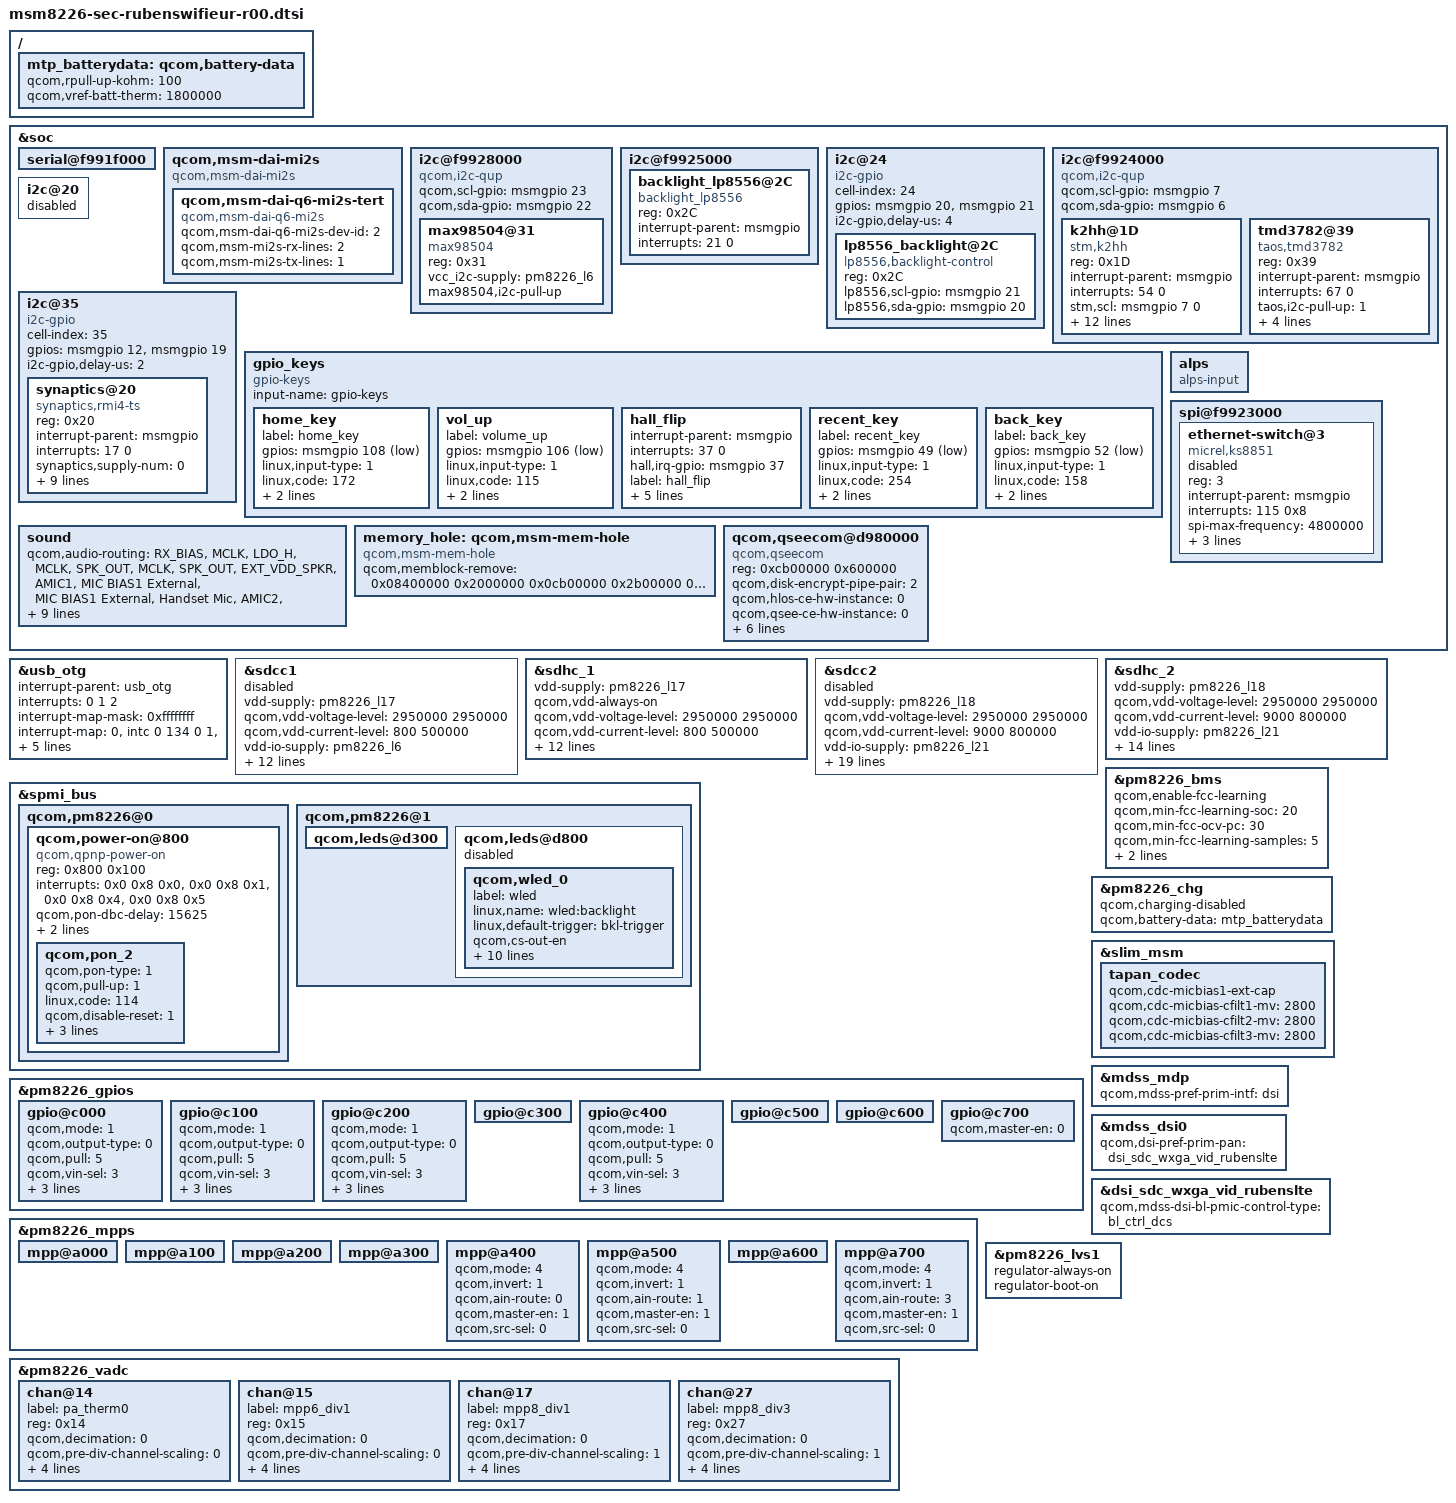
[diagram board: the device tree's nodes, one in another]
/* Copyright (c) 2013, The Linux Foundation. All rights reserved.
 *
 * This program is free software; you can redistribute it and/or modify
 * it under the terms of the GNU General Public License version 2 and
 * only version 2 as published by the Free Software Foundation.
 *
 * This program is distributed in the hope that it will be useful,
 * but WITHOUT ANY WARRANTY; without even the implied warranty of
 * MERCHANTABILITY or FITNESS FOR A PARTICULAR PURPOSE.  See the
 * GNU General Public License for more details.
 */

/include/ "msm8226-camera-sensor-mtp-rubenswifi_eur-r00.dtsi"
/include/ "dsi_panel_sdc_wxga_video_rubenslte.dtsi"
/include/ "msm8226-sec-rubenswifieur-battery-data.dtsi"

&soc {
	serial@f991f000 {
		status = "ok";
	};
/*# CONFIG_SND_SOC_MAX98504*/
		qcom,msm-dai-mi2s {
			compatible = "qcom,msm-dai-mi2s";
			qcom,msm-dai-q6-mi2s-tert {
			compatible = "qcom,msm-dai-q6-mi2s";
			qcom,msm-dai-q6-mi2s-dev-id = <2>;
			qcom,msm-mi2s-rx-lines = <2>;
			qcom,msm-mi2s-tx-lines = <1>;
		};
	};
	
    	i2c@f9928000 {	 /*BLSP-1 QUP-6*/
		compatible = "qcom,i2c-qup";
		qcom,scl-gpio = <&msmgpio 23 0>;
		qcom,sda-gpio = <&msmgpio 22 0>;
		max98504@31 {
			compatible = "max98504";
			reg = <0x31>;
			vcc_i2c-supply = <&pm8226_l6>;
			max98504,i2c-pull-up;
		};
	};// CONFIG_SND_SOC_MAX98504
	
	 /*
	i2c@f9925000 {
		sec-nfc@27 {
			compatible = "sec-nfc";
			reg = <0x27>;
			interrupt-parent = <&msmgpio>;
			interrupts = <21 0>;
			vdd_nfc-supply = <&pm8226_l6>;
			sec-nfc,en-gpio = <&msmgpio 36 0x1>;
			sec-nfc,wake-gpio = <&msmgpio 20 0x00>;
		};
	};*/

	i2c@f9925000 { /* BLSP1 QUP2 */
/*	i2c@75 {
		cell-index = <75>;
		compatible = "i2c-gpio";
		gpios = <&msmgpio 20 0
			&msmgpio 21 0>;};*/

	backlight_lp8556@2C {
			compatible = "backlight_lp8556";
			reg = <0x2C>;
			interrupt-parent = <&msmgpio>;
			interrupts = <21 0>;
		};
	};

	i2c@24 {
                cell-index = <24>;
                compatible = "i2c-gpio";
                gpios = <&msmgpio 20 0 /* sda */
                                &msmgpio 21 0 /* scl */
                >;

                i2c-gpio,delay-us = <4>;

                lp8556_backlight@2C {
                                compatible = "lp8556,backlight-control";
                                reg = <0x2C>;
                                lp8556,scl-gpio = <&msmgpio 21 0x00>;
                                lp8556,sda-gpio = <&msmgpio 20 0x00>;
                };
        };

	i2c@f9924000 { /* BLSP1 QUP2 */
		compatible = "qcom,i2c-qup";
		qcom,scl-gpio = <&msmgpio 7 0>;
		qcom,sda-gpio = <&msmgpio 6 0>;
		k2hh@1D {
			compatible = "stm,k2hh";
			reg = <0x1D>;
			interrupt-parent = <&msmgpio>;
			interrupts = <54 0>;
			stm,scl = <&msmgpio 7 0>;
			stm,sda = <&msmgpio 6 0>;
			stm,irq_gpio = <&msmgpio 54 0x00>;
			stm,reg_vdd = "8226_l19";
			stm,reg_vio = "8226_lvs1";
			stm,axis_map_x = <1>;
			stm,axis_map_y = <0>;
			stm,axis_map_z = <2>;
			stm,negate_x = <0>;
			stm,negate_y = <1>;
			stm,negate_z = <1>;
			stm,poll_interval = <100>;
			stm,min_interval = <2>;
		};

		tmd3782@39 {
			compatible = "taos,tmd3782";
			reg = <0x39>;
			interrupt-parent = <&msmgpio>;
			interrupts = <67 0>;
			taos,i2c-pull-up = <1>;
			taos,reg_vdd = "8226_l19";
			taos,reg_vio = "8226_l6";
			taos,reg_ldo = "8226_l15";
			taos,irq_gpio = <&msmgpio 67 0x1>;
			status = "okay";
		};
	};

	i2c@20 {
		status="disabled";
	};

	i2c@35{
		cell-index = <35>;
		compatible = "i2c-gpio";
		gpios = <&msmgpio 12 0 /* sda */
				 &msmgpio 19 0 /* scl */
				>;
		i2c-gpio,delay-us = <2>;
                synaptics@20 {
                        compatible = "synaptics,rmi4-ts";
                        reg = <0x20>;
                        interrupt-parent = <&msmgpio>;
                        interrupts = <17 0>;
                        synaptics,supply-num = <0>;                     /* the number of regulators */
                        synaptics,external_ldo = <&msmgpio 31 0x01>; /*Touch En 1 gpio*/
                        synaptics,external_ldo2 = <&msmgpio 114 0x01>; /* Touch En2 gpio */
                        synaptics,irq-gpio = <&msmgpio 17 0x00>;
                        synaptics,reset-gpio = <&msmgpio 34 0x00>;
                        synaptics,i2c-pull-up = <1>;
                        synaptics,tsp-project = "RUBENS";
                        synaptics,tsp-coords = <1599 2559>;
                        synaptics,tsp-extra_config = <0 0 0 1>;
                        synaptics,id-gpio = <&msmgpio 55 0x01>;
                        /* <"pwrctrl", "N", "N", "irq no pull up, workaround"> */
                        /* Set regulators' voltage below. Search with "8941_l22", "8941_l10" */
                };

	};
	gpio_keys {
		compatible = "gpio-keys";
		input-name = "gpio-keys";

		home_key {
			label = "home_key";
			gpios = <&msmgpio 108 0x1>;
			linux,input-type = <1>;
			linux,code = <172>;
			gpio-key,wakeup;
			debounce-interval = <15>;
		};


		vol_up {
			label = "volume_up";
			gpios = <&msmgpio 106 0x1>;
			linux,input-type = <1>;
			linux,code = <115>;
			gpio-key,wakeup;
			debounce-interval = <15>;
		};

		hall_flip {
			interrupt-parent = <&msmgpio>;
			interrupts = <37 0>;
			hall,irq-gpio = <&msmgpio 37 0x00>;

			label = "hall_flip";
			gpios = <&msmgpio 37 0>;
			linux,input-type = <1>;
			linux,code = <0x15>;
			gpio-key,wakeup;
			debounce-interval = <15>;
		};
		recent_key {
			label = "recent_key";
			gpios = <&msmgpio 49 0x1>;
			linux,input-type = <1>;
			linux,code = <254>;
			gpio-key,wakeup;
			debounce-interval = <15>;
		};
		back_key {
			label = "back_key";
			gpios = <&msmgpio 52 0x1>;
			linux,input-type = <1>;
			linux,code = <158>;
			gpio-key,wakeup;
			debounce-interval = <15>;
		};
	};
	alps {
			compatible = "alps-input";
	};

	spi@f9923000 {
		ethernet-switch@3 {
			compatible = "micrel,ks8851";
			reg = <3>;
			interrupt-parent = <&msmgpio>;
			interrupts = <115 0x8>;
			spi-max-frequency = <4800000>;
			rst-gpio = <&msmgpio 114 0>;
			vdd-io-supply = <&pm8226_lvs1>;
			vdd-phy-supply = <&pm8226_lvs1>;
			status = "disable";
		};
	};

	sound {
		qcom,audio-routing =
			"RX_BIAS", "MCLK",
			"LDO_H", "MCLK",
			"SPK_OUT", "MCLK",
			"SPK_OUT", "EXT_VDD_SPKR",
			"AMIC1", "MIC BIAS1 External",
			"MIC BIAS1 External", "Handset Mic",
			"AMIC2", "MIC BIAS2 External",
			"MIC BIAS2 External", "Headset Mic",
			"AMIC3", "MIC BIAS3 External",
			"MIC BIAS3 External", "Sub Mic",
			"AMIC4", "MIC BIAS2 External",
			"MIC BIAS2 External", "ANCRight Headset Mic",
			"AMIC5", "MIC BIAS2 External",
			"MIC BIAS2 External", "ANCLeft Headset Mic";

		qcom,cdc-mclk-gpios = <&pm8226_gpios 1 0>;
		/*qcom,cdc-vdd-spkr-gpios = <&pm8226_gpios 2 0>;*/
		vdd-earjack-supply = <&pm8226_l19>;
	};

	memory_hole: qcom,msm-mem-hole {
		     compatible = "qcom,msm-mem-hole";
		     qcom,memblock-remove = <0x08400000 0x2000000
					     0x0cb00000 0x2b00000 /* Increase TZ apps region to 6MB (SR #0133393) + 1MB reserved for TIMA logging at 0xd100000 */
					     0x0fa00000 0x500000>; /* Address and Size of Hole */
	};

	qcom,qseecom@d980000 {
		compatible = "qcom,qseecom";
		reg = <0xcb00000 0x600000>;
		reg-names = "secapp-region";
		qcom,disk-encrypt-pipe-pair = <2>;
		qcom,hlos-ce-hw-instance = <0>;
		qcom,qsee-ce-hw-instance = <0>;
		qcom,msm-bus,name = "qseecom-noc";
		qcom,msm-bus,num-cases = <4>;
		/* qcom,msm-bus,active-only = <0>; */
		qcom,msm-bus,num-paths = <1>;
		qcom,msm-bus,vectors-KBps =
				<55 512 0 0>,
				<55 512 3936000 393600>,
				<55 512 3936000 393600>,
				<55 512 3936000 393600>;
	};
};

&usb_otg {
	#address-cells = <0>;
	interrupt-parent = <&usb_otg>;
	interrupts = <0 1 2>;
	#interrupt-cells = <1>;
	interrupt-map-mask = <0xffffffff>;
	interrupt-map = <0 &intc 0 134 0
			1 &intc 0 140 0
			2 &spmi_bus 0x0 0x0 0x9 0x0>;
	interrupt-names = "core_irq", "async_irq", "pmic_id_irq";

	qcom,hsusb-otg-mode = <3>;
	vbus_otg-supply = <&pm8226_chg_otg>;
	qcom,hsusb-otg-phy-init-seq =
			<0x44 0x80 0x6F 0x81 0x24 0x82 0x13 0x83 0xffffffff>;
};

&sdcc1 {
	vdd-supply = <&pm8226_l17>;
	qcom,vdd-voltage-level = <2950000 2950000>;
	qcom,vdd-current-level = <800 500000>;

	vdd-io-supply = <&pm8226_l6>;
	qcom,vdd-io-always-on;
	qcom,vdd-io-voltage-level = <1800000 1800000>;
	qcom,vdd-io-current-level = <250 154000>;

	qcom,pad-pull-on = <0x0 0x3 0x3>; /* no-pull, pull-up, pull-up */
	qcom,pad-pull-off = <0x0 0x3 0x3>; /* no-pull, pull-up, pull-up */
	qcom,pad-drv-on = <0x4 0x4 0x4>; /* 10mA, 10mA, 10mA */
	qcom,pad-drv-off = <0x0 0x0 0x0>; /* 2mA, 2mA, 2mA */

	qcom,clk-rates = <400000 25000000 50000000 100000000 200000000>;
	qcom,sup-voltages = <2950 2950>;

	qcom,bus-speed-mode = "HS200_1p8v", "DDR_1p8v";
	qcom,nonremovable;

	status = "disabled";
};

&sdhc_1 {
	vdd-supply = <&pm8226_l17>;
	qcom,vdd-always-on;
	qcom,vdd-voltage-level = <2950000 2950000>;
	qcom,vdd-current-level = <800 500000>;

	vdd-io-supply = <&pm8226_l6>;
	qcom,vdd-io-always-on;
	qcom,vdd-io-voltage-level = <1800000 1800000>;
	qcom,vdd-io-current-level = <250 154000>;

	qcom,pad-pull-on = <0x0 0x3 0x3>; /* no-pull, pull-up, pull-up */
	qcom,pad-pull-off = <0x0 0x3 0x3>; /* no-pull, pull-up, pull-up */
	qcom,pad-drv-on = <0x4 0x4 0x4>; /* 10mA, 10mA, 10mA */
	qcom,pad-drv-off = <0x0 0x0 0x0>; /* 2mA, 2mA, 2mA */

	qcom,clk-rates = <400000 25000000 50000000 100000000 200000000>;
	qcom,bus-speed-mode = "HS200_1p8v", "DDR_1p8v";
	qcom,nonremovable;

	status = "ok";
};

&sdcc2 {
	vdd-supply = <&pm8226_l18>;
	qcom,vdd-voltage-level = <2950000 2950000>;
	qcom,vdd-current-level = <9000 800000>;

	vdd-io-supply = <&pm8226_l21>;
	qcom,vdd-io-voltage-level = <1800000 2950000>;
	qcom,vdd-io-current-level = <6 22000>;

	qcom,pad-pull-on = <0x0 0x3 0x3>; /* no-pull, pull-up, pull-up */
	qcom,pad-pull-off = <0x0 0x3 0x3>; /* no-pull, pull-up, pull-up */
	qcom,pad-drv-on = <0x4 0x4 0x4>; /* 10mA, 10mA, 10mA */
	qcom,pad-drv-off = <0x0 0x0 0x0>; /* 2mA, 2mA, 2mA */

	qcom,clk-rates = <400000 25000000 50000000 100000000 200000000>;
	qcom,sup-voltages = <2950 2950>;

	qcom,xpc;
	qcom,bus-speed-mode = "SDR12", "SDR25", "SDR50", "DDR50", "SDR104";
	qcom,current-limit = <600>; #address-cells = <0>; interrupt-parent = <&sdcc2>;
	interrupts = <0 1 2>;
	#interrupt-cells = <1>;
	interrupt-map-mask = <0xffffffff>;
	interrupt-map = <0 &intc 0 125 0
			1 &intc 0 220 0
			2 &msmgpio 38 0x3>;
	interrupt-names = "core_irq", "bam_irq", "status_irq";
	cd-gpios = <&msmgpio 38 0x1>;

	status = "disabled";
};

&sdhc_2 {
	vdd-supply = <&pm8226_l18>;
	qcom,vdd-voltage-level = <2950000 2950000>;
	qcom,vdd-current-level = <9000 800000>;

	vdd-io-supply = <&pm8226_l21>;
	qcom,vdd-io-voltage-level = <1800000 2950000>;
	qcom,vdd-io-current-level = <6 22000>;

	qcom,pad-pull-on = <0x0 0x3 0x3>; /* no-pull, pull-up, pull-up */
	qcom,pad-pull-off = <0x0 0x3 0x3>; /* no-pull, pull-up, pull-up */
	qcom,pad-drv-on = <0x4 0x3 0x4>; /* 10mA, 8mA, 10mA */
	qcom,pad-drv-off = <0x0 0x0 0x0>; /* 2mA, 2mA, 2mA */

	qcom,clk-rates = <400000 25000000 50000000 100000000 200000000>;

	#address-cells = <0>;
	interrupt-parent = <&sdhc_2>;
	interrupts = <0 1 2>;
	#interrupt-cells = <1>;
	interrupt-map-mask = <0xffffffff>;
	interrupt-map = <0 &intc 0 125 0
			1 &intc 0 221 0
			2 &msmgpio 38 0x3>;
	interrupt-names = "hc_irq", "pwr_irq", "status_irq";
	cd-gpios = <&msmgpio 38 0x1>;

	status = "ok";
};

&spmi_bus {
	 qcom,pm8226@0 {
                qcom,power-on@800 {
                        compatible = "qcom,qpnp-power-on";
                        reg = <0x800 0x100>;
                        interrupts = <0x0 0x8 0x0>,
                                     <0x0 0x8 0x1>,
                                     <0x0 0x8 0x4>,
                                     <0x0 0x8 0x5>;
                        interrupt-names = "kpdpwr", "resin",
                                        "resin-bark", "kpdpwr-resin-bark";
                        qcom,pon-dbc-delay = <15625>;
                        qcom,system-reset;
                        qcom,s3-debounce = <128>;

                        qcom,pon_2 {
                                qcom,pon-type = <1>;
                                qcom,pull-up = <1>;
                                linux,code = <114>;
                                qcom,disable-reset = <1>;
                                qcom,s1-timer = <6720>;
                                qcom,s2-timer = <2000>;
                                qcom,s2-type = <7>;
                        };

                };
        };


	qcom,pm8226@1 {
                qcom,leds@d300 {
                        status = "okay";
                };

		qcom,leds@d800 {
			status = "disabled"; /*If WLED is not used for Backlight control*/
			qcom,wled_0 {		/*for TFT Panel, this to be disabled */
				label = "wled";
				linux,name = "wled:backlight";
				linux,default-trigger = "bkl-trigger";
				qcom,cs-out-en;
				qcom,op-fdbck = <1>;
				qcom,default-state = "off";
				qcom,max-current = <20>;
				qcom,ctrl-delay-us = <0>;
				qcom,boost-curr-lim = <3>;
				qcom,cp-sel = <0>;
				qcom,switch-freq = <11>;
				qcom,ovp-val = <0>;
				qcom,num-strings = <1>;
				qcom,id = <0>;
			};
		};
	};
};

&pm8226_gpios {
	gpio@c000 { /* GPIO 1 */
		/* XO_PMIC_CDC_MCLK enable for tapan codec */
		qcom,mode = <1>;		/* Digital output */
		qcom,output-type = <0>;	/* CMOS logic */
		qcom,pull = <5>;		/* QPNP_PIN_PULL_NO*/
		qcom,vin-sel = <3>;		/* QPNP_PIN_VIN3 */
		qcom,out-strength = <3>;/* QPNP_PIN_OUT_STRENGTH_HIGH */
		qcom,src-sel = <2>;		/* QPNP_PIN_SEL_FUNC_1 */
		qcom,master-en = <1>;	/* Enable GPIO */
	};

	gpio@c100 { /* GPIO 2 */
		qcom,mode = <1>;
		qcom,output-type = <0>;
		qcom,pull = <5>;
		qcom,vin-sel = <3>;
		qcom,out-strength = <3>;
		qcom,src-sel = <2>;
		qcom,master-en = <1>;
	};

	gpio@c200 { /* GPIO 3 */
		qcom,mode = <1>;		/* Digital output */
		qcom,output-type = <0>;	/* CMOS logic */
		qcom,pull = <5>;		/* QPNP_PIN_PULL_NO*/
		qcom,vin-sel = <3>;		/* QPNP_PIN_VIN3 */
		qcom,out-strength = <3>;/* QPNP_PIN_OUT_STRENGTH_HIGH */
		qcom,src-sel = <2>;		/* QPNP_PIN_SEL_FUNC_1 */
		qcom,master-en = <1>;	/* Enable GPIO */
	};

	gpio@c300 { /* GPIO 4 */
	};

	gpio@c400 { /* GPIO 5 */
		qcom,mode = <1>;		/* Digital output */
		qcom,output-type = <0>;	/* CMOS logic */
		qcom,pull = <5>;		/* QPNP_PIN_PULL_NO */
		qcom,vin-sel = <3>;		/* QPNP_PIN_VIN2 */
		qcom,out-strength = <3>;/* QPNP_PIN_OUT_STRENGTH_HIGH */
		qcom,src-sel = <2>;		/* QPNP_PIN_SEL_FUNC_1 */
		qcom,master-en = <1>;
	};

	gpio@c500 { /* GPIO 6 */
	};

	gpio@c600 { /* GPIO 7 */
	};

	gpio@c700 { /* GPIO 8 */
		qcom,master-en = <0>;
	};
};

&pm8226_mpps {
	mpp@a000 { /* MPP 1 */
	};

	mpp@a100 { /* MPP 2 */
	};

	mpp@a200 { /* MPP 3 */
	};

	mpp@a300 { /* MPP 4 */
	};

	mpp@a400 { /* MPP 5 */
		/* PA_THERM0 config */
		qcom,mode = <4>; /* AIN input */
		qcom,invert = <1>; /* Enable MPP */
		qcom,ain-route = <0>; /* AMUX 5 */
		qcom,master-en = <1>;
		qcom,src-sel = <0>; /* Function constant */
	};

	mpp@a500 { /* MPP 6 */
		qcom,mode = <4>; /* AIN input */
		qcom,invert = <1>; /* Enable MPP */
		qcom,ain-route = <1>; /* AMUX 6 */
		qcom,master-en = <1>;
		qcom,src-sel = <0>; /* Function constant */
	};

	mpp@a600 { /* MPP 7 */
	};

	mpp@a700 { /* MPP 8 */
		/* PA_THERM1 config */
		qcom,mode = <4>; /* AIN input */
		qcom,invert = <1>; /* Enable MPP */
		qcom,ain-route = <3>; /* AMUX 8 */
		qcom,master-en = <1>;
		qcom,src-sel = <0>; /* Function constant */
	};
};

&pm8226_vadc {
	chan@14 {
		label = "pa_therm0";
		reg = <0x14>;
		qcom,decimation = <0>;
		qcom,pre-div-channel-scaling = <0>;
		qcom,calibration-type = "ratiometric";
		qcom,scale-function = <2>;
		qcom,hw-settle-time = <2>;
		qcom,fast-avg-setup = <0>;
	};

	chan@15 {
		label = "mpp6_div1";
		reg = <0x15>;
		qcom,decimation = <0>;
		qcom,pre-div-channel-scaling = <0>;
		qcom,calibration-type = "absolute";
		qcom,scale-function = <0>;
		qcom,hw-settle-time = <0>;
		qcom,fast-avg-setup = <0>;
	};
	chan@17 {
		label = "pa_therm1";
		reg = <0x17>;
		qcom,decimation = <0>;
		qcom,pre-div-channel-scaling = <0>;
		qcom,calibration-type = "ratiometric";
		qcom,scale-function = <2>;
		qcom,hw-settle-time = <2>;
		qcom,fast-avg-setup = <0>;
	};

	chan@17 {
		label = "mpp8_div1";
		reg = <0x17>;
		qcom,decimation = <0>;
		qcom,pre-div-channel-scaling = <1>;
		qcom,calibration-type = "absolute";
		qcom,scale-function = <0>;
		qcom,hw-settle-time = <0>;
		qcom,fast-avg-setup = <0>;
		};

	chan@27 {
		label = "mpp8_div3";
		reg = <0x27>;
		qcom,decimation = <0>;
		qcom,pre-div-channel-scaling = <1>;
		qcom,calibration-type = "absolute";
		qcom,scale-function = <0>;
		qcom,hw-settle-time = <0>;
		qcom,fast-avg-setup = <0>;
		};
};

/ {
	mtp_batterydata: qcom,battery-data {
		qcom,rpull-up-kohm = <100>;
		qcom,vref-batt-therm = <1800000>;

		/include/ "batterydata-palladium.dtsi"
		/include/ "batterydata-mtp-3000mah.dtsi"
	};
};

&pm8226_bms {
	status = "ok";
	qcom,enable-fcc-learning;
	qcom,min-fcc-learning-soc = <20>;
	qcom,min-fcc-ocv-pc = <30>;
	qcom,min-fcc-learning-samples = <5>;
	qcom,fcc-resolution = <10>;
	qcom,battery-data = <&mtp_batterydata>;
};

&pm8226_chg {
	qcom,charging-disabled;
	qcom,battery-data = <&mtp_batterydata>;
};

&slim_msm {
	tapan_codec {
		qcom,cdc-micbias1-ext-cap;
		qcom,cdc-micbias-cfilt1-mv = <2800>;
		qcom,cdc-micbias-cfilt2-mv = <2800>;
		qcom,cdc-micbias-cfilt3-mv = <2800>;
	};
};

&mdss_mdp {
	qcom,mdss-pref-prim-intf = "dsi";
};

&mdss_dsi0 {
	qcom,dsi-pref-prim-pan = <&dsi_sdc_wxga_vid_rubenslte>;
};

&dsi_sdc_wxga_vid_rubenslte {
	qcom,mdss-dsi-bl-pmic-control-type = "bl_ctrl_dcs";
};

&pm8226_lvs1 {
		regulator-always-on;
		regulator-boot-on;
};
